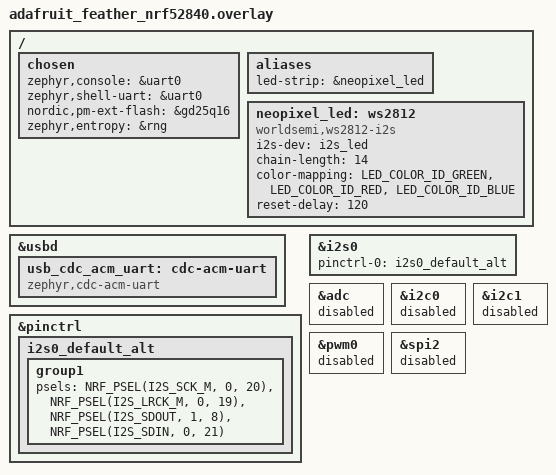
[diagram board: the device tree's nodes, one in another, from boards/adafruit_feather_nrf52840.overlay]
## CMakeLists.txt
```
#
# Copyright (c) 2021 Nordic Semiconductor ASA
#
# SPDX-License-Identifier: LicenseRef-Nordic-5-Clause
#

cmake_minimum_required(VERSION 3.20.0)

get_filename_component(MATTER_MODULE_ROOT $ENV{ZEPHYR_BASE}/../modules/lib/matter REALPATH)

# Set Kconfig root files that will be processed as a first Kconfig for used child images.
set(mcuboot_KCONFIG_ROOT ${MATTER_MODULE_ROOT}/config/nrfconnect/chip-module/Kconfig.mcuboot.root)
set(multiprotocol_rpmsg_KCONFIG_ROOT ${MATTER_MODULE_ROOT}/config/nrfconnect/chip-module/Kconfig.multiprotocol_rpmsg.root)

find_package(Zephyr HINTS $ENV{ZEPHYR_BASE})

project(feedback-light)

set(COMMON_ROOT src/common)
set(NLIO_ROOT ${MATTER_MODULE_ROOT}/third_party/nlio/repo)
include(${MATTER_MODULE_ROOT}/config/nrfconnect/app/enable-gnu-std.cmake)
include(${MATTER_MODULE_ROOT}/src/app/chip_data_model.cmake)

# NORDIC SDK APP START
target_include_directories(app PRIVATE
    src
    ${COMMON_ROOT}
    ${NLIO_ROOT}/include
    ${MATTER_MODULE_ROOT}/zzz_generated/app-common
)

target_sources(app PRIVATE
    src/app_task.cpp
    src/main.cpp
    src/led_strip.cpp
    src/zcl_callbacks.cpp
    src/zap-generated/IMClusterCommandHandler.cpp
    src/zap-generated/callback-stub.cpp
    ${COMMON_ROOT}/led_widget.cpp
)

chip_configure_data_model(app
    INCLUDE_SERVER
    BYPASS_IDL
    GEN_DIR src/zap-generated
    ZAP_FILE ${CMAKE_CURRENT_SOURCE_DIR}/src/feedback_light.zap
)
# NORDIC SDK APP END


# Compiler warnings to error
zephyr_library_compile_options(-Werror)
```

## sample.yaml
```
sample:
  description: Feedback Light
  name: Feedback Light
tests:
  gentlyCommunicatingHome.feedback_light:
    platform_allow: adafruit_feather_nrf52840 xiao_ble_sense
```

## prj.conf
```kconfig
#################
# Debugging
#################
CONFIG_DEBUG=y
CONFIG_DEBUG_OPTIMIZATIONS=y
CONFIG_STD_CPP14=y
CONFIG_DEBUG_INFO=y
CONFIG_EXCEPTION_STACK_TRACE=y
CONFIG_THREAD_NAME=y
CONFIG_MPU_STACK_GUARD=y
CONFIG_RESET_ON_FATAL_ERROR=n


#################
# Memory settings
#################
CONFIG_ISR_STACK_SIZE=4096
CONFIG_SYSTEM_WORKQUEUE_STACK_SIZE=2560


#################
# Matter
#################
CONFIG_CHIP=y
CONFIG_CHIP_PROJECT_CONFIG="src/chip_project_config.h"
# 32773 == 0x8005 (example lighting-app)
CONFIG_CHIP_DEVICE_PRODUCT_ID=32773

CONFIG_CHIP_ENABLE_PAIRING_AUTOSTART=y
CONFIG_CHIP_OTA_REQUESTOR=n
CONFIG_CHIP_NFC_COMMISSIONING=n
CONFIG_CHIP_QSPI_NOR=n

# Disable factory data support. 
CONFIG_CHIP_FACTORY_DATA=n
CONFIG_CHIP_FACTORY_DATA_BUILD=n


#################
# Openthread
#################
CONFIG_NET_L2_OPENTHREAD=y
CONFIG_OPENTHREAD_DEFAULT_TX_POWER=3


####################################
# Bluetooth Low Energy configuration
####################################
CONFIG_BT_DEVICE_NAME="FeedbackLight"


###################
# USB configuration
###################
CONFIG_USB_DEVICE_STACK=y
CONFIG_USB_DEVICE_PRODUCT="FeedbackLight"
CONFIG_USB_CDC_ACM=y
CONFIG_UART_LINE_CTRL=y

# The build should not complain about using the default device ids
CONFIG_USB_DEVICE_VID=0x1234
CONFIG_USB_DEVICE_PID=0x5678

CONFIG_USB_DEVICE_MANUFACTURER="J"
CONFIG_USB_DEVICE_SN="MLB_000000000000"

CONFIG_USB_DEVICE_INITIALIZE_AT_BOOT=y

CONFIG_USB_COMPOSITE_DEVICE=n
#CONFIG_USB_MAX_NUM_TRANSFERS=8


#######
# Shell
#######
CONFIG_SHELL=y
CONFIG_SHELL_PROMPT_UART="$ "
CONFIG_SHELL_BACKEND_SERIAL_CHECK_DTR=y
CONFIG_SHELL_VT100_COMMANDS=n
CONFIG_SHELL_DEFAULT_TERMINAL_WIDTH=100
CONFIG_SHELL_STACK_SIZE=3168
CONFIG_SHELL_CMD_BUFF_SIZE=128
CONFIG_SHELL_BACKEND_SERIAL_RX_RING_BUFFER_SIZE=128

CONFIG_OPENTHREAD_SHELL=n
CONFIG_CHIP_LIB_SHELL=n


##########
# logging
##########
CONFIG_LOG=y
CONFIG_LOG_MODE_MINIMAL=n
CONFIG_LOG_MODE_DEFERRED=n
CONFIG_LOG_MODE_IMMEDIATE=y
CONFIG_LOG_BUFFER_SIZE=8192
CONFIG_LOG_BACKEND_SHOW_COLOR=n 

CONFIG_LOG_BACKEND_UART=y
CONFIG_SHELL_LOG_BACKEND=n

# Logs when using Debugger.
CONFIG_USE_SEGGER_RTT=n
#CONFIG_LOG_BACKEND_RTT=y
#CONFIG_LOG_BACKEND_RTT_MODE_DROP=y
#CONFIG_LOG_BACKEND_RTT_MESSAGE_SIZE=256
#CONFIG_SHELL_BACKEND_RTT=n
#CONFIG_SEGGER_RTT_BUFFER_SIZE_UP=4096

CONFIG_MATTER_LOG_LEVEL_DBG=y
CONFIG_LED_STRIP_LOG_LEVEL_DBG=y
CONFIG_USB_CDC_ACM_LOG_LEVEL_OFF=y


############
# App
############
CONFIG_LED_STRIP=y
CONFIG_WS2812_STRIP=y

CONFIG_I2S=y
CONFIG_WS2812_STRIP_I2S=y

# Add support for LEDs and buttons on Nordic development kits
CONFIG_DK_LIBRARY=y
```

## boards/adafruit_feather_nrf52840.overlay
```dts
#include <zephyr/dt-bindings/led/led.h>

 / {
	chosen {
		zephyr,console = &uart0;
		zephyr,shell-uart = &uart0;
		nordic,pm-ext-flash = &gd25q16;
		zephyr,entropy = &rng;
	};

	aliases {
		led-strip = &neopixel_led;
	};
};

zephyr_udc: &usbd {
	usb_cdc_acm_uart: cdc-acm-uart {
		compatible = "zephyr,cdc-acm-uart";
	};
};

&pinctrl {
	i2s0_default_alt: i2s0_default_alt {
		group1 {
			psels = <NRF_PSEL(I2S_SCK_M, 0, 20)>,
				<NRF_PSEL(I2S_LRCK_M, 0, 19)>,
				<NRF_PSEL(I2S_SDOUT, 1, 8)>,
				<NRF_PSEL(I2S_SDIN, 0, 21)>;
		};
	};
};

i2s_led: &i2s0 {
	status = "okay";
	pinctrl-0 = <&i2s0_default_alt>;
	pinctrl-names = "default";
};

/ {
	neopixel_led: ws2812 {
		compatible = "worldsemi,ws2812-i2s";

		i2s-dev = < &i2s_led >;
		chain-length = <14>; /* arbitrary; change at will */
		color-mapping = 
		<LED_COLOR_ID_GREEN>,
		<LED_COLOR_ID_RED>,
		<LED_COLOR_ID_BLUE>;
		reset-delay = <120>;
	};
};



/* Disable unused peripherals to reduce power consumption */
&adc {
	status = "disabled";
};
&i2c0 {
	status = "disabled";
};
&i2c1 {
	status = "disabled";
};
&pwm0 {
	status = "disabled";
};
&spi2 {
	status = "disabled";
};
//&uart0 {
//	status = "disabled";
//};
```

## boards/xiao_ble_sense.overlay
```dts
#include <zephyr/dt-bindings/led/led.h>

 / {
	chosen {
		zephyr,console = &usb_cdc_acm_uart;
		zephyr,shell-uart = &usb_cdc_acm_uart;
		nordic,pm-ext-flash = &p25q16h;
		zephyr,entropy = &rng;
	};

	aliases {
		led-strip = &neopixel_led;
	};
};

&pinctrl {
	i2s0_default_alt: i2s0_default_alt {
		group1 {
			psels = <NRF_PSEL(I2S_SCK_M, 0, 20)>,
				<NRF_PSEL(I2S_LRCK_M, 0, 19)>,
				<NRF_PSEL(I2S_SDOUT, 0, 29)>,
				<NRF_PSEL(I2S_SDIN, 0, 21)>;
		};
	};
};

i2s_led: &i2s0 {
	status = "okay";
	pinctrl-0 = <&i2s0_default_alt>;
	pinctrl-names = "default";
};

/ {
	neopixel_led: ws2812 {
		compatible = "worldsemi,ws2812-i2s";

		i2s-dev = < &i2s_led >;
		chain-length = <25>; /* arbitrary; change at will */
		color-mapping = 
		<LED_COLOR_ID_GREEN>,
		<LED_COLOR_ID_RED>,
		<LED_COLOR_ID_BLUE>;
		reset-delay = <120>;
	};
};



/* Disable unused peripherals to reduce power consumption */
&adc {
	status = "disabled";
};
&i2c0 {
	status = "disabled";
};
&i2c1 {
	status = "disabled";
};
&pwm0 {
	status = "disabled";
};
&spi2 {
	status = "disabled";
};
&uart0 {
	status = "disabled";
};

/delete-node/ &lsm6ds3tr_c;
```

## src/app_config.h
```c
/*
 * Copyright (c) 2022 Nordic Semiconductor ASA
 *
 * SPDX-License-Identifier: LicenseRef-Nordic-5-Clause
 */

#pragma once

/* ---- Light Bulb App Config ---- */

#define FUNCTION_BUTTON DK_BTN1
#define FUNCTION_BUTTON_MASK DK_BTN1_MSK

#define SYSTEM_STATE_LED DK_LED1
#define FACTORY_RESET_SIGNAL_LED DK_LED2
```

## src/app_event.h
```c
/*
 * Copyright (c) 2021 Nordic Semiconductor ASA
 *
 * SPDX-License-Identifier: LicenseRef-Nordic-5-Clause
 */

#pragma once

#include <cstdint>

class LEDWidget;

enum class LightingAction : uint8_t {
  None = 0,
  SetLevel,
  SetEnable,
  SetHue,
  SetSaturation,
  SetHueSaturation,
  Blink,
};

enum class AppEventType : uint8_t {
  None = 0,
  Button,
  ButtonPushed,
  ButtonReleased,
  Timer,
  UpdateLedState,
  Lighting,
  IdentifyStart,
  IdentifyStop,
};

enum class FunctionEvent : uint8_t { NoneSelected = 0, FactoryReset };

struct AppEvent;
using EventHandler = void (*)(const AppEvent &);

struct AppEvent {
  union {
    struct {
      uint8_t PinNo;
      uint8_t Action;
    } ButtonEvent;
    struct {
      void *Context;
    } TimerEvent;
    struct {
      LightingAction Action;
      uint32_t Value;
      uint8_t Value2;
      bool isRelative;
    } LightingEvent;
    struct {
      LEDWidget *LedWidget;
    } UpdateLedStateEvent;
  };

  AppEventType Type{AppEventType::None};
  EventHandler Handler;
};
```

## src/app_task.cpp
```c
/*
 * Copyright (c) 2021 Nordic Semiconductor ASA
 *
 * SPDX-License-Identifier: LicenseRef-Nordic-5-Clause
 */

#include "app_task.h"

#include <app-common/zap-generated/attributes/Accessors.h>
#include <app/DeferredAttributePersistenceProvider.h>
#include <app/clusters/identify-server/identify-server.h>
#include <app/server/OnboardingCodesUtil.h>
#include <app/server/Server.h>
#include <credentials/DeviceAttestationCredsProvider.h>
#include <credentials/examples/DeviceAttestationCredsExample.h>
#include <dk_buttons_and_leds.h>
#include <lib/support/CHIPMem.h>
#include <lib/support/CodeUtils.h>
#include <platform/CHIPDeviceLayer.h>
#include <system/SystemError.h>
#include <zephyr/kernel.h>
#include <zephyr/logging/log.h>

#include "app_config.h"
#include "led_strip.h"
#include "led_widget.h"

LOG_MODULE_DECLARE(app, CONFIG_CHIP_APP_LOG_LEVEL);

using namespace ::chip;
using namespace ::chip::app;
using namespace ::chip::Credentials;
using namespace ::chip::DeviceLayer;

namespace {
constexpr uint32_t factoryResetTriggerTimeout = 6000;
constexpr size_t appEventQueueSize = 10;
constexpr EndpointId lightEndpointId = 1;
constexpr uint8_t defaultMinLevel = 0;
constexpr uint8_t defaultMaxLevel = 254;

K_MSGQ_DEFINE(appEventQueue, sizeof(AppEvent), appEventQueueSize, alignof(AppEvent));
k_timer functionTimer;

Identify identify = {lightEndpointId, AppTask::IdentifyStartHandler, AppTask::IdentifyStopHandler,
                     EMBER_ZCL_IDENTIFY_IDENTIFY_TYPE_VISIBLE_LED, NULL};

LEDWidget statusLED;
LEDWidget factoryResetLED;
LedStrip light;

bool isNetworkProvisioned = false;
bool isNetworkEnabled = false;
bool haveBLEConnections = false;

// Define a custom attribute persister which makes actual write of the CurrentLevel attribute value
// to the non-volatile storage only when it has remained constant for 5 seconds. This is to reduce
// the flash wearout when the attribute changes frequently as a result of MoveToLevel command.
// DeferredAttribute object describes a deferred attribute, but also holds a buffer with a value to
// be written, so it must live so long as the DeferredAttributePersistenceProvider object.

DeferredAttribute deferredAttributes[] = {
    DeferredAttribute(ConcreteAttributePath(lightEndpointId, Clusters::LevelControl::Id,
                                            Clusters::LevelControl::Attributes::CurrentLevel::Id)),
    DeferredAttribute(ConcreteAttributePath(lightEndpointId, Clusters::ColorControl::Id,
                                            Clusters::ColorControl::Attributes::CurrentHue::Id)),
    DeferredAttribute(ConcreteAttributePath(lightEndpointId, Clusters::ColorControl::Id,
                              Clusters::ColorControl::Attributes::CurrentSaturation::Id)),
};

DeferredAttributePersistenceProvider deferredAttributePersister(
    Server::GetInstance().GetDefaultAttributePersister(),
    Span<DeferredAttribute>(deferredAttributes, 3), System::Clock::Milliseconds32(5000));

} /* namespace */

namespace LedConsts {
constexpr uint32_t identifyBlinkRate_ms{500};

namespace StatusLed {
namespace Unprovisioned {
constexpr uint32_t on_ms{100};
constexpr uint32_t off_ms{on_ms};
}  // namespace Unprovisioned
namespace Provisioned {
constexpr uint32_t on_ms{50};
constexpr uint32_t off_ms{950};
}  // namespace Provisioned

}  // namespace StatusLed

}  // namespace LedConsts

CHIP_ERROR AppTask::Init() {
  /* Initialize CHIP stack */
  LOG_INF("Init CHIP stack");

  CHIP_ERROR err = chip::Platform::MemoryInit();
  if (err != CHIP_NO_ERROR) {
    LOG_ERR("Platform::MemoryInit() failed");
    return err;
  }

  err = PlatformMgr().InitChipStack();
  if (err != CHIP_NO_ERROR) {
    LOG_ERR("PlatformMgr().InitChipStack() failed");
    return err;
  }

  err = ThreadStackMgr().InitThreadStack();
  if (err != CHIP_NO_ERROR) {
    LOG_ERR("ThreadStackMgr().InitThreadStack() failed: %s", ErrorStr(err));
    return err;
  }

  err = ConnectivityMgr().SetThreadDeviceType(ConnectivityManager::kThreadDeviceType_Router);

  if (err != CHIP_NO_ERROR) {
    LOG_ERR("ThreadStackMgr().InitThreadStack() failed: %s", ErrorStr(err));
    return err;
  }

  /* Initialize LEDs */
  LEDWidget::InitGpio();
  LEDWidget::SetStateUpdateCallback(LEDStateUpdateHandler);

  statusLED.Init(SYSTEM_STATE_LED);
  factoryResetLED.Init(FACTORY_RESET_SIGNAL_LED);

  UpdateStatusLED();

  /* Initialize buttons */
  int ret = dk_buttons_init(ButtonEventHandler);
  if (ret) {
    LOG_ERR("dk_buttons_init() failed");
    return chip::System::MapErrorZephyr(ret);
  }

  /* Initialize function timer */
  k_timer_init(&functionTimer, &AppTask::FunctionTimerTimeoutCallback, nullptr);
  k_timer_user_data_set(&functionTimer, this);

  /* Initialize lighting device (PWM) */
  uint8_t minLightLevel = defaultMinLevel;
  Clusters::LevelControl::Attributes::MinLevel::Get(lightEndpointId, &minLightLevel);

  uint8_t maxLightLevel = defaultMaxLevel;
  Clusters::LevelControl::Attributes::MaxLevel::Get(lightEndpointId, &maxLightLevel);

  light.init(defaultMinLevel, defaultMaxLevel);

  /* Initialize CHIP server */
#if CONFIG_CHIP_FACTORY_DATA
  ReturnErrorOnFailure(mFactoryDataProvider.Init());
  SetDeviceInstanceInfoProvider(&mFactoryDataProvider);
  SetDeviceAttestationCredentialsProvider(&mFactoryDataProvider);
  SetCommissionableDataProvider(&mFactoryDataProvider);
#else
  SetDeviceInstanceInfoProvider(&DeviceInstanceInfoProviderMgrImpl());
  SetDeviceAttestationCredentialsProvider(Examples::GetExampleDACProvider());
#endif

  static chip::CommonCaseDeviceServerInitParams initParams;
  (void)initParams.InitializeStaticResourcesBeforeServerInit();

  ReturnErrorOnFailure(chip::Server::GetInstance().Init(initParams));
  app::SetAttributePersistenceProvider(&deferredAttributePersister);

  ConfigurationMgr().LogDeviceConfig();
  PrintOnboardingCodes(chip::RendezvousInformationFlags(chip::RendezvousInformationFlag::kBLE));

  /*
   * Add CHIP event handler and start CHIP thread.
   * Note that all the initialization code should happen prior to this point to avoid data races
   * between the main and the CHIP threads.
   */
  PlatformMgr().AddEventHandler(ChipEventHandler, 0);

  err = PlatformMgr().StartEventLoopTask();
  if (err != CHIP_NO_ERROR) {
    LOG_ERR("PlatformMgr().StartEventLoopTask() failed");
    return err;
  }

  return CHIP_NO_ERROR;
}

CHIP_ERROR AppTask::StartApp() {
  ReturnErrorOnFailure(Init());

  AppEvent event = {};

  while (true) {
    k_msgq_get(&appEventQueue, &event, K_FOREVER);
    DispatchEvent(event);
  }

  return CHIP_NO_ERROR;
}

void AppTask::IdentifyStartHandler(Identify *) {
  LOG_INF("Start identifying");
  AppEvent event;
  event.Type = AppEventType::IdentifyStart;
  event.Handler = [](const AppEvent &) {
    light.blink(LedConsts::identifyBlinkRate_ms, LedConsts::identifyBlinkRate_ms);
  };
  PostEvent(event);
}

void AppTask::IdentifyStopHandler(Identify *) {
  LOG_INF("Stop identifying");
  AppEvent event;
  event.Type = AppEventType::IdentifyStop;
  event.Handler = [](const AppEvent &) { light.blink(0, 0); };
  PostEvent(event);
}

void AppTask::ZCLHandler(const AppEvent &event) {
  LOG_INF("ZCLHandler with AppEvent type %d, action %d, value %d", (uint8_t)event.Type,
          (uint8_t)event.LightingEvent.Action, event.LightingEvent.Value);
  AppEvent ev(event);
  ev.Handler = LightingActionEventHandler;
  PostEvent(ev);
}

void AppTask::LightingActionEventHandler(const AppEvent &event) {
  LOG_INF("LightingActionEventHandler with AppEvent type %d, action %d, value %d",
          (uint8_t)event.Type, (uint8_t)event.LightingEvent.Action, event.LightingEvent.Value);
  if (event.Type == AppEventType::Button) {
    light.isTurnedOn() ? light.enable(false) : light.enable(true);
    Instance().UpdateClusterState();
  } else if (event.Type == AppEventType::Lighting) {
    switch (event.LightingEvent.Action) {
      case LightingAction::SetEnable:
        light.enable(event.LightingEvent.Value);
        break;
      case LightingAction::SetLevel:
        light.setLevel(event.LightingEvent.Value);
        break;
      case LightingAction::SetHue:
        light.setHue(event.LightingEvent.Value, event.LightingEvent.isRelative);
        break;
      case LightingAction::SetSaturation:
        light.setSaturation(event.LightingEvent.Value, event.LightingEvent.isRelative);
        break;
      case LightingAction::SetHueSaturation:
        light.setHue(event.LightingEvent.Value, event.LightingEvent.isRelative);
        light.setSaturation(event.LightingEvent.Value2, event.LightingEvent.isRelative);
        break;
      default:
        break;
    }
  }
}

void AppTask::ButtonEventHandler(uint32_t buttonState, uint32_t hasChanged) {
  AppEvent button_event;
  button_event.Type = AppEventType::Button;

  if (FUNCTION_BUTTON_MASK & hasChanged) {
    button_event.ButtonEvent.PinNo = FUNCTION_BUTTON;
    button_event.ButtonEvent.Action =
        static_cast<uint8_t>((FUNCTION_BUTTON_MASK & buttonState) ? AppEventType::ButtonPushed
                                                                  : AppEventType::ButtonReleased);
    button_event.Handler = FunctionHandler;
    PostEvent(button_event);
  }
}

void AppTask::FunctionTimerTimeoutCallback(k_timer *timer) {
  if (!timer) {
    return;
  }

  AppEvent event;
  event.Type = AppEventType::Timer;
  event.TimerEvent.Context = k_timer_user_data_get(timer);
  event.Handler = FunctionTimerEventHandler;
  PostEvent(event);
}

void AppTask::FunctionTimerEventHandler(const AppEvent &event) {
  if (event.Type != AppEventType::Timer) {
    return;
  }

  if (Instance().mFunction == FunctionEvent::FactoryReset) {
    Instance().mFunction = FunctionEvent::NoneSelected;
    LOG_INF("Factory Reset triggered");

    statusLED.Set(true);
    factoryResetLED.Set(true);

    chip::Server::GetInstance().ScheduleFactoryReset();
  }
}

void AppTask::FunctionHandler(const AppEvent &event) {
  if (event.ButtonEvent.PinNo != FUNCTION_BUTTON) return;

  if (event.ButtonEvent.Action == static_cast<uint8_t>(AppEventType::ButtonPushed)) {
    Instance().StartTimer(factoryResetTriggerTimeout);
    Instance().mFunction = FunctionEvent::FactoryReset;
  } else if (event.ButtonEvent.Action == static_cast<uint8_t>(AppEventType::ButtonReleased)) {
    if (Instance().mFunction == FunctionEvent::FactoryReset) {
      factoryResetLED.Set(false);
      UpdateStatusLED();
      Instance().CancelTimer();
      Instance().mFunction = FunctionEvent::NoneSelected;
      LOG_INF("Factory Reset has been Canceled. Toggle Light.");

      AppEvent button_event;
      button_event.Type = AppEventType::Button;
      button_event.Handler = LightingActionEventHandler;
      PostEvent(button_event);
    }
  }
}

void AppTask::LEDStateUpdateHandler(LEDWidget &ledWidget) {
  AppEvent event;
  event.Type = AppEventType::UpdateLedState;
  event.Handler = UpdateLedStateEventHandler;
  event.UpdateLedStateEvent.LedWidget = &ledWidget;
  PostEvent(event);
}

void AppTask::UpdateLedStateEventHandler(const AppEvent &event) {
  if (event.Type == AppEventType::UpdateLedState) {
    event.UpdateLedStateEvent.LedWidget->UpdateState();
  }
}

void AppTask::UpdateStatusLED() {
  /* Update the status LED.
   *
   * If IPv6 networking and service provisioned, keep the LED On constantly.
   *
   * If the system has BLE connection(s) uptill the stage above, THEN blink the LED at an even
   * rate of 100ms.
   *
   * Otherwise, blink the LED for a very short time. */
  if (isNetworkProvisioned && isNetworkEnabled) {
    statusLED.Set(true);
  } else if (haveBLEConnections) {
    statusLED.Blink(LedConsts::StatusLed::Unprovisioned::on_ms,
                    LedConsts::StatusLed::Unprovisioned::off_ms);
  } else {
    statusLED.Blink(LedConsts::StatusLed::Provisioned::on_ms,
                    LedConsts::StatusLed::Provisioned::off_ms);
  }
}

void AppTask::ChipEventHandler(const ChipDeviceEvent *event, intptr_t /* arg */) {
  switch (event->Type) {
    case DeviceEventType::kCHIPoBLEAdvertisingChange:
      haveBLEConnections = ConnectivityMgr().NumBLEConnections() != 0;
      UpdateStatusLED();
      break;
    case DeviceEventType::kDnssdInitialized:
      break;
    case DeviceEventType::kThreadStateChange:
      isNetworkProvisioned = ConnectivityMgr().IsThreadProvisioned();
      isNetworkEnabled = ConnectivityMgr().IsThreadEnabled();
      UpdateStatusLED();
      break;
    default:
      break;
  }
}

void AppTask::CancelTimer() { k_timer_stop(&functionTimer); }

void AppTask::StartTimer(uint32_t timeoutInMs) {
  k_timer_start(&functionTimer, K_MSEC(timeoutInMs), K_NO_WAIT);
}

void AppTask::PostEvent(const AppEvent &event) {
  if (k_msgq_put(&appEventQueue, &event, K_NO_WAIT) != 0) {
    LOG_INF("Failed to post event to app task event queue");
  }
}

void AppTask::DispatchEvent(const AppEvent &event) {
  if (event.Handler) {
    event.Handler(event);
  } else {
    LOG_INF("Event received with no handler. Dropping event.");
  }
}

void AppTask::UpdateClusterState() {
  SystemLayer().ScheduleLambda([this] {
    // write the new on/off value
    EmberAfStatus status =
        Clusters::OnOff::Attributes::OnOff::Set(lightEndpointId, light.isTurnedOn());

    if (status != EMBER_ZCL_STATUS_SUCCESS) {
      LOG_ERR("Updating on/off cluster failed: %x", status);
    }

    // write the current level
    status =
        Clusters::LevelControl::Attributes::CurrentLevel::Set(lightEndpointId, light.getLevel());

    if (status != EMBER_ZCL_STATUS_SUCCESS) {
      LOG_ERR("Updating level cluster failed: %x", status);
    }

    // write the color hue
    status = Clusters::ColorControl::Attributes::CurrentHue::Set(lightEndpointId, light.getHue());

    if (status != EMBER_ZCL_STATUS_SUCCESS) {
      LOG_ERR("Updating level cluster failed: %x", status);
    }

    // write the color saturation
    status = Clusters::ColorControl::Attributes::CurrentSaturation::Set(lightEndpointId,
                                                                        light.getSaturation());

    if (status != EMBER_ZCL_STATUS_SUCCESS) {
      LOG_ERR("Updating level cluster failed: %x", status);
    }

    LOG_INF("Updated cluster state endpoint %d to : %d level %d", lightEndpointId,
            light.isTurnedOn(), light.getLevel());
  });
}
```

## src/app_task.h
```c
/*
 * Copyright (c) 2021 Nordic Semiconductor ASA
 *
 * SPDX-License-Identifier: LicenseRef-Nordic-5-Clause
 */

#pragma once

#include "app_event.h"
#include "led_widget.h"

#include <platform/CHIPDeviceLayer.h>

#if CONFIG_CHIP_FACTORY_DATA
#include <platform/nrfconnect/FactoryDataProvider.h>
#else
#include <platform/nrfconnect/DeviceInstanceInfoProviderImpl.h>
#endif

struct k_timer;
struct Identify;

class AppTask {
public:
	static AppTask &Instance()
	{
		static AppTask sAppTask;
		return sAppTask;
	};

	CHIP_ERROR StartApp();

	void UpdateClusterState();

	static void IdentifyStartHandler(Identify *);
	static void IdentifyStopHandler(Identify *);

	void ZCLHandler(const AppEvent &event);
private:
	CHIP_ERROR Init();

	void CancelTimer();
	void StartTimer(uint32_t timeoutInMs);

	static void PostEvent(const AppEvent &event);
	static void DispatchEvent(const AppEvent &event);
	static void UpdateLedStateEventHandler(const AppEvent &event);
	static void FunctionHandler(const AppEvent &event);
	static void FunctionTimerEventHandler(const AppEvent &event);
	static void LightingActionEventHandler(const AppEvent &event);

	static void ChipEventHandler(const chip::DeviceLayer::ChipDeviceEvent *event, intptr_t arg);
	static void ButtonEventHandler(uint32_t buttonState, uint32_t hasChanged);
	static void FunctionTimerTimeoutCallback(k_timer *timer);

	static void UpdateStatusLED();
	static void LEDStateUpdateHandler(LEDWidget &ledWidget);

	FunctionEvent mFunction = FunctionEvent::NoneSelected;
	bool mFunctionTimerActive = false;

#if CONFIG_CHIP_FACTORY_DATA
	chip::DeviceLayer::FactoryDataProvider<chip::DeviceLayer::InternalFlashFactoryData> mFactoryDataProvider;
#endif
};
```

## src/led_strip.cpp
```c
#include "led_strip.h"

#include <zephyr/device.h>
#include <zephyr/drivers/led_strip.h>
#include <zephyr/logging/log.h>

LOG_MODULE_DECLARE(app, CONFIG_CHIP_APP_LOG_LEVEL);

#include <algorithm>
#include <cmath>

// Following two functions by alexkuhl colorspace-conversion-library
//   from https://github.com/alexkuhl/colorspace-conversion-library

/*
Copyright (c) 2010, Alex Kuhl, http://www.alexkuhl.org
All rights reserved.

Redistribution and use in source and binary forms, with or without
modification, are permitted provided that the following conditions are
met:

    * Redistributions of source code must retain the above copyright
      notice, this list of conditions and the following disclaimer.
    * Redistributions in binary form must reproduce the above
      copyright notice, this list of conditions and the following
      disclaimer in the documentation and/or other materials provided
      with the distribution.
    * Neither the name of the author nor the names of other
      contributors may be used to endorse or promote products derived
      from this software without specific prior written permission.

THIS SOFTWARE IS PROVIDED BY THE COPYRIGHT HOLDERS AND CONTRIBUTORS
"AS IS" AND ANY EXPRESS OR IMPLIED WARRANTIES, INCLUDING, BUT NOT
LIMITED TO, THE IMPLIED WARRANTIES OF MERCHANTABILITY AND FITNESS FOR
A PARTICULAR PURPOSE ARE DISCLAIMED. IN NO EVENT SHALL THE COPYRIGHT
OWNER OR CONTRIBUTORS BE LIABLE FOR ANY DIRECT, INDIRECT, INCIDENTAL,
SPECIAL, EXEMPLARY, OR CONSEQUENTIAL DAMAGES (INCLUDING, BUT NOT
LIMITED TO, PROCUREMENT OF SUBSTITUTE GOODS OR SERVICES; LOSS OF USE,
DATA, OR PROFITS; OR BUSINESS INTERRUPTION) HOWEVER CAUSED AND ON ANY
THEORY OF LIABILITY, WHETHER IN CONTRACT, STRICT LIABILITY, OR TORT
(INCLUDING NEGLIGENCE OR OTHERWISE) ARISING IN ANY WAY OUT OF THE USE
OF THIS SOFTWARE, EVEN IF ADVISED OF THE POSSIBILITY OF SUCH DAMAGE.
*/

/* A small, easy-to-understand C++ library written to convert colorspaces
 * Will convert RGB to HSV or HSL and back to RGB
 * Note on the colors:
 * R,G,B are ints [0,255]
 * S,V,L are floats [0,1]
 * H is a float [0,360)
 *
 * Requires the CImg library header file (testing code used version 1.3.1)
 * http://cimg.sourceforge.net/
 */

// -- start
#pragma GCC diagnostic push
#pragma GCC diagnostic ignored "-Wnarrowing"
void hsl_to_rgb(float h, float s, float l, int &r, int &g, int &b) {
  float q;
  if (l < .5)
    q = l * (1 + s);
  else
    q = l + s - (l * s);
  float p = 2 * l - q;
  h /= 360;
  // t holds r, g, and b values
  float t[3] = {h + 1 / 3.0, h, h - 1 / 3.0};
  for (int i = 0; i < 3; ++i) {
    if (t[i] < 0)
      t[i] += 1;
    else if (t[i] > 1)
      t[i] -= 1;
    // calculate the color
    if (t[i] < 1.0 / 6.0)
      t[i] = p + ((q - p) * 6 * t[i]);
    else if (1.0 / 6.0 <= t[i] && t[i] < .5)
      t[i] = q;
    else if (.5 <= t[i] && t[i] < 2.0 / 3.0)
      t[i] = p + ((q - p) * 6 * (2.0 / 3.0 - t[i]));
    else
      t[i] = p;
  }
  r = round(t[0] * 255);
  g = round(t[1] * 255);
  b = round(t[2] * 255);
}

void rgb_to_hsl(int r, int g, int b, float &h, float &s, float &l) {
  float fr = r / 255.0, fg = g / 255.0, fb = b / 255.0;
  int imax = std::max(std::max(r, g), b);
  int imin = std::min(std::min(r, g), b);
  float fmax = imax / 255.0;
  float fmin = imin / 255.0;
  float multiplier = (imin == imax) ? 0.0 : 60 / (fmax - fmin);

  if (r == imax)  // red is dominant
  {
    h = (multiplier * (fg - fb) + 360);
    if (h >= 360) h -= 360;  // take quick modulus, % doesn't work with floats
  } else if (g == imax)      // green is dominant
    h = multiplier * (fb - fr) + 120;
  else  // blue is dominant
    h = multiplier * (fr - fg) + 240;
  l = .5 * (fmax + fmin);
  if (imax == imin)
    s = 0.0;
  else if (l <= .5)
    s = (fmax - fmin) / (2 * l);
  else
    s = (fmax - fmin) / (2 - 2 * l);
}
#pragma GCC diagnostic pop
// -- end

void LedStrip::init(uint8_t minLevel, uint8_t maxLevel) {
  if (!device_is_ready(strip)) {
    LOG_ERR("LED strip device %s is not ready", strip->name);
  }

  mMinLevel = minLevel;
  mMaxLevel = maxLevel;

  // mColorHsl is active on startup
  mColorRgb = COLOR_RGB_WHITE;
  mColorHsl = COLOR_HSL_WHITE;

  mState = stateOff;
  mBlinkOnTimeMS = 0;
  mBlinkOffTimeMS = 0;

  k_timer_init(&mLedTimer, &LedStrip::ledStateTimerHandlerEntry, nullptr);
  k_timer_user_data_set(&mLedTimer, this);

  LOG_INF("Init LED strip device %s level min-max (%d-%d) to color GREEN state off", strip->name,
          minLevel, maxLevel);
  apply();
}

void LedStrip::enable(bool on) {
  LOG_INF("LED strip enable %s", on ? "on" : "off");

  mState = on ? stateOn : stateOff;
  mBlinkOnTimeMS = 0;
  mBlinkOffTimeMS = 0;

  apply();
}

void LedStrip::setLevel(uint8_t level) {
  LOG_INF("LED strip set level to %d", level);

  if (level < mMinLevel) level = mMinLevel;
  if (level > mMaxLevel) level = mMaxLevel;

  mColorHsl.l = (float)level / (float)mMaxLevel;
  mBlinkOnTimeMS = 0;
  mBlinkOffTimeMS = 0;

  apply();
}

void LedStrip::setColor(uint32_t rgba) {
  uint8_t *p = (uint8_t *)&rgba;
  setColor(p[0], p[1], p[2]);
}

void LedStrip::setColor(uint8_t r, uint8_t g, uint8_t b) {
  LOG_INF("LED strip set color to (%d,%d,%d)", r, g, b);

  mColorRgb = RGB(r, g, b);
  mBlinkOnTimeMS = 0;
  mBlinkOffTimeMS = 0;

  rgb_to_hsl(mColorRgb.r, mColorRgb.g, mColorRgb.b, mColorHsl.h, mColorHsl.s, mColorHsl.l);

  apply();
}

void LedStrip::setHue(uint8_t h, bool isRelative) {
  float hue = (float)h * mMaxHueInternal / mMaxHueInterface;
  if (isRelative) {
    mColorHsl.h += hue;
  } else {
    mColorHsl.h = hue;
  }

  if (mColorHsl.h > mMaxHueInternal) {
    mColorHsl.h = mColorHsl.h - mMaxHueInternal;
  }
  if (mColorHsl.h < 0.0) {
    mColorHsl.h = mMaxHueInternal - mColorHsl.h;
  }

  apply();
}

void LedStrip::setSaturation(uint8_t s, bool isRelative) {
  float saturation = (float)s / mMaxSaturationInterface;
  if (isRelative) {
    mColorHsl.s += saturation;
  } else {
    mColorHsl.s = saturation;
  }

  if (mColorHsl.s > mMaxSaturationInternal) {
    mColorHsl.s = mColorHsl.s - mMaxSaturationInternal;
  }
  if (mColorHsl.s < 0.0) {
    mColorHsl.s = mMaxSaturationInternal - mColorHsl.s;
  }

  apply();
}

uint32_t LedStrip::getColor() {
  uint8_t rgba[4];
  rgba[0] = mColorRgb.r;
  rgba[1] = mColorRgb.g;
  rgba[2] = mColorRgb.b;
  rgba[3] = 0xFF;
  uint32_t *p32 = (uint32_t *)rgba;
  return *p32;
}

void LedStrip::blink(uint32_t onTimeMS, uint32_t offTimeMS) {
  LOG_INF("LED strip blink for %d - %d", onTimeMS, offTimeMS);

  k_timer_stop(&mLedTimer);

  mBlinkOnTimeMS = onTimeMS;
  mBlinkOffTimeMS = offTimeMS;

  if (mBlinkOnTimeMS != 0 && mBlinkOffTimeMS != 0) {
    scheduleStateChange();
  }
}

void LedStrip::apply() {
  LOG_INF("apply color to original: hsl(%f,%f,%f) state=%d", mColorHsl.h, mColorHsl.s, mColorHsl.l,
          mState);

  int r, g, b;
  hsl_to_rgb(mColorHsl.h, mColorHsl.s, mColorHsl.l, r, g, b);

  struct led_rgb rgb_color = RGB((uint8_t)r, (uint8_t)g, (uint8_t)b);

  LOG_INF("converted color values: rgb(%d,%d,%d) -- int rgb(%d,%d,%d)", rgb_color.r, rgb_color.g,
          rgb_color.b, r, g, b);

  memset(&mPixels, 0x00, sizeof(mPixels));
  if (mState == stateOn) {
    for (auto &pixel : mPixels) {
      memcpy(&pixel, &rgb_color, sizeof(struct led_rgb));
    }
  }

  LOG_HEXDUMP_INF(mPixels, sizeof(struct led_rgb) * pixelCount, "mPixels data");

  int rc = led_strip_update_rgb(strip, mPixels, pixelCount);

  if (rc) {
    LOG_ERR("couldn't update strip: %d", rc);
  }
}

void LedStrip::scheduleStateChange() {
  k_timer_start(&mLedTimer, K_MSEC(mState ? mBlinkOnTimeMS : mBlinkOffTimeMS), K_NO_WAIT);
}

void LedStrip::ledStateTimerHandlerEntry(k_timer *timer) {
  LedStrip *light = reinterpret_cast<LedStrip *>(k_timer_user_data_get(timer));
  light->ledStateTimerHandler();
}

void LedStrip::ledStateTimerHandler() {
  LOG_INF("blink timer timeout. timing: %d,%d", mBlinkOnTimeMS, mBlinkOffTimeMS);

  if (mBlinkOnTimeMS != 0 && mBlinkOffTimeMS != 0) {
    mState = (mState == stateOn) ? stateOff : stateOn;
    apply();
    scheduleStateChange();
  }
}
```

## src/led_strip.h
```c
#pragma once

#include <zephyr/device.h>
#include <zephyr/drivers/led_strip.h>
#include <zephyr/kernel.h>

#define RGB(_r, _g, _b) \
  { .r = (_r), .g = (_g), .b = (_b) }

#define HSL(_h, _s, _l) \
  { .h = (_h), .s = (_s), .l = (_l) }

#define COLOR_RGB_WHITE RGB(0xff, 0xff, 0xff)
#define COLOR_HSL_GREEN HSL(85.0, 1.0, 0.5)
#define COLOR_HSL_WHITE HSL(85.0, 1.0, 1.0)
#define LED_DEVICE_NODE DT_ALIAS(led_strip)

struct led_hsl {
  float h; // range 0.0 - 360.0
  float s; // range 0.0 -   1.0
  float l; // range 0.0 -   1.0
};

class LedStrip {
 public:
  void init(uint8_t minLevel, uint8_t maxLevel);
  void enable(bool on);
  void setLevel(uint8_t level);
  void setColor(uint32_t rgba);
  void setColor(uint8_t r, uint8_t g, uint8_t b);
  void setHue(uint8_t h, bool isRelative);
  void setSaturation(uint8_t s, bool isRelative);
  void blink(uint32_t onTimeMS, uint32_t offTimeMS);
  bool isTurnedOn() const { return mState == stateOn; }
  uint8_t getLevel() const { return (uint8_t)(mColorHsl.l * mMaxLevel); }
  uint8_t getMinLevel() const { return mMinLevel; }
  uint8_t getMaxLevel() const { return mMaxLevel; }
  uint32_t getColor();
  uint8_t getHue() {return (uint8_t)(mColorHsl.h / mMaxHueInternal * mMaxHueInterface); }
  uint8_t getSaturation() {return (uint8_t)(mColorHsl.s * mMaxSaturationInterface); }
  static void ledStateTimerHandlerEntry(k_timer *timer);
  void ledStateTimerHandler();

 private:
  void apply();
  void scheduleStateChange();

  static constexpr uint16_t pixelCount = DT_PROP(DT_ALIAS(led_strip), chain_length);

  enum State_t : uint8_t {
    stateOn = 0,
    stateOff,
  };

  k_timer mLedTimer;
  k_timer mUpdateTimer;
  uint32_t mBlinkOnTimeMS;
  uint32_t mBlinkOffTimeMS;

  State_t mState;
  uint8_t mMinLevel;
  uint8_t mMaxLevel;
  uint8_t mMaxHueInterface = 254;
  float mMaxHueInternal = 360.0;
  uint8_t mMaxSaturationInterface = 254;
  float mMaxSaturationInternal = 1.0;
  struct led_rgb mColorRgb;
  struct led_hsl mColorHsl;

  const struct device *const strip = DEVICE_DT_GET(LED_DEVICE_NODE);
  struct led_rgb mPixels[pixelCount];
};
```

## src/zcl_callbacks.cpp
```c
/*
 * Copyright (c) 2021 Nordic Semiconductor ASA
 *
 * SPDX-License-Identifier: LicenseRef-Nordic-5-Clause
 */

#include <app-common/zap-generated/attributes/Accessors.h>
#include <app-common/zap-generated/ids/Attributes.h>
#include <app-common/zap-generated/ids/Clusters.h>
#include <app/CommandHandler.h>
#include <app/ConcreteAttributePath.h>
#include <app/ConcreteCommandPath.h>
#include <lib/support/logging/CHIPLogging.h>

#include "app_task.h"

#define MIN_HUE_VALUE 0
#define MAX_HUE_VALUE 254

#define MIN_SATURATION_VALUE 0
#define MAX_SATURATION_VALUE 254

using namespace ::chip;
using namespace ::chip::app::Clusters;
using namespace ::chip::Protocols::InteractionModel;

void MatterPostAttributeChangeCallback(const app::ConcreteAttributePath &attributePath,
                                       uint8_t type, uint16_t size, uint8_t *value) {
  ClusterId clusterId = attributePath.mClusterId;
  AttributeId attributeId = attributePath.mAttributeId;

  if (clusterId == OnOff::Id && attributeId == OnOff::Attributes::OnOff::Id) {
    ChipLogProgress(Zcl, "Cluster OnOff: attribute OnOff set to %" PRIu8 "", *value);
    AppEvent event;
    event.Type = AppEventType::Lighting;
    event.LightingEvent.Action = LightingAction::SetEnable;
    event.LightingEvent.Value = *value;
    AppTask::Instance().ZCLHandler(event);
  } else if (clusterId == LevelControl::Id &&
             attributeId == LevelControl::Attributes::CurrentLevel::Id) {
    ChipLogProgress(Zcl, "Cluster LevelControl: attribute CurrentLevel set to %" PRIu8 "", *value);
    AppEvent event;
    event.Type = AppEventType::Lighting;
    event.LightingEvent.Action = LightingAction::SetLevel;
    event.LightingEvent.Value = *value;
    AppTask::Instance().ZCLHandler(event);
  } else if (clusterId == ColorControl::Id &&
             attributeId == ColorControl::Attributes::CurrentHue::Id) {
    ChipLogProgress(Zcl, "Cluster LevelControl: attribute CurrentHue set to %" PRIu8 "", *value);
    AppEvent event;
    event.Type = AppEventType::Lighting;
    event.LightingEvent.Action = LightingAction::SetHue;
    event.LightingEvent.Value = *value;
    event.LightingEvent.isRelative = false;
    AppTask::Instance().ZCLHandler(event);
  } else if (clusterId == ColorControl::Id &&
             attributeId == ColorControl::Attributes::CurrentSaturation::Id) {
    ChipLogProgress(Zcl, "Cluster LevelControl: attribute CurrentSaturation set to %" PRIu8 "",
                    *value);
    AppEvent event;
    event.Type = AppEventType::Lighting;
    event.LightingEvent.Action = LightingAction::SetSaturation;
    event.LightingEvent.Value = *value;
    event.LightingEvent.isRelative = false;
    AppTask::Instance().ZCLHandler(event);
  } else {
    ChipLogProgress(
        Zcl, "MatterPostAttributeChangeCallback(clusterId=%d, attributeId=%d) NOT HANDLED!!!",
        clusterId, attributeId);
  }
}

/** @brief OnOff Cluster Init
 *
 * This function is called when a specific cluster is initialized. It gives the
 * application an opportunity to take care of cluster initialization procedures.
 * It is called exactly once for each endpoint where cluster is present.
 *
 * @param endpoint   Ver.: always
 *
 * TODO Issue #3841
 * emberAfOnOffClusterInitCallback happens before the stack initialize the cluster
 * attributes to the default value.
 * The logic here expects something similar to the deprecated Plugins callback
 * emberAfPluginOnOffClusterServerPostInitCallback.
 *
 */
void emberAfOnOffClusterInitCallback(EndpointId endpoint) {
  EmberAfStatus status;
  bool storedValue;

  /* Read storedValue on/off value */
  status = OnOff::Attributes::OnOff::Get(endpoint, &storedValue);
  if (status == EMBER_ZCL_STATUS_SUCCESS) {
    /* Set actual state to the cluster state that was last persisted */
    AppEvent event;
    event.Type = AppEventType::Lighting;
    event.LightingEvent.Action = LightingAction::SetEnable;
    event.LightingEvent.Value = storedValue;
    AppTask::Instance().ZCLHandler(event);
  }
  AppTask::Instance().UpdateClusterState();
}

void emberAfColorControlClusterInitCallback(EndpointId endpoint) {
  EmberAfStatus status;
  uint8_t storedHue;
  uint8_t storedSaturation;

  status = ColorControl::Attributes::CurrentHue::Get(endpoint, &storedHue);
  if (status != EMBER_ZCL_STATUS_SUCCESS) {
    status = ColorControl::Attributes::CurrentSaturation::Get(endpoint, &storedSaturation);
    if (status == EMBER_ZCL_STATUS_SUCCESS) {
      // Set actual state to the cluster state that was last persisted
      AppEvent event;
      event.Type = AppEventType::Lighting;
      event.LightingEvent.Action = LightingAction::SetHueSaturation;
      event.LightingEvent.Value = storedHue;
      event.LightingEvent.Value2 = storedSaturation;
      event.LightingEvent.isRelative = false;
      AppTask::Instance().ZCLHandler(event);
      ChipLogProgress(Zcl, "emberAfOnOffClusterInitCallback: restore the hue %d and saturation %d",
                      storedHue, storedSaturation);
    }
  }
}
```
